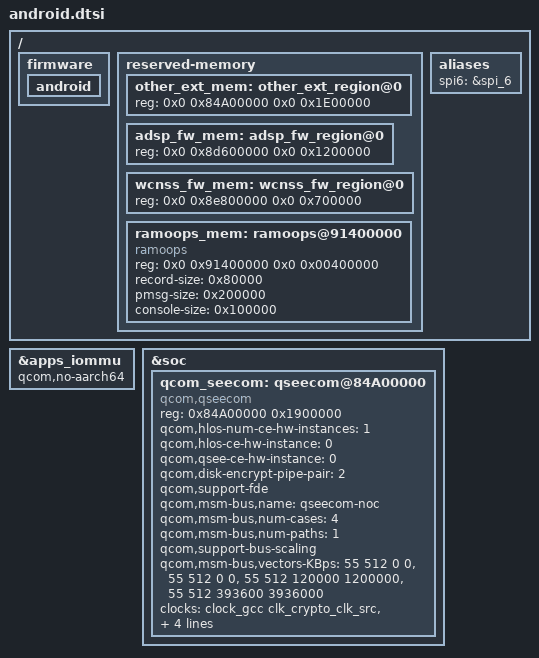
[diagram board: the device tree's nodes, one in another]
/ {
	firmware: firmware {
		android {
			/delete-node/ fstab;
			/delete-node/ vbmeta;
		};
	};

	reserved-memory {
		other_ext_mem: other_ext_region@0 {
			reg = <0x0 0x84A00000 0x0 0x1E00000>;
		};

		adsp_fw_mem: adsp_fw_region@0 {
			reg = <0x0 0x8d600000 0x0 0x1200000>;
		};

		wcnss_fw_mem: wcnss_fw_region@0 {
			reg = <0x0 0x8e800000 0x0 0x700000>;
		};

		/* ramoops: kernel log persistence across reboots.
		 * 4MB at 0x91400000 — allows grabbing last_kmsg after bootloop.
		 */
		ramoops_mem: ramoops@91400000 {
			compatible = "ramoops";
			reg = <0x0 0x91400000 0x0 0x00400000>;
			record-size = <0x80000>;
			pmsg-size = <0x200000>;
			console-size = <0x100000>;
		};
	};

	aliases {
		spi6 = &spi_6;
	};
};

&apps_iommu {
	qcom,no-aarch64;
};

&soc {
	/delete-node/ qseecom@85b00000;

	qcom_seecom: qseecom@84A00000 {
		compatible = "qcom,qseecom";
		reg = <0x84A00000 0x1900000>;
		reg-names = "secapp-region";
		qcom,hlos-num-ce-hw-instances = <1>;
		qcom,hlos-ce-hw-instance = <0>;
		qcom,qsee-ce-hw-instance = <0>;
		qcom,disk-encrypt-pipe-pair = <2>;
		qcom,support-fde;
		qcom,msm-bus,name = "qseecom-noc";
		qcom,msm-bus,num-cases = <4>;
		qcom,msm-bus,num-paths = <1>;
		qcom,support-bus-scaling;
		qcom,msm-bus,vectors-KBps =
			<55 512 0 0>,
			<55 512 0 0>,
			<55 512 120000 1200000>,
			<55 512 393600 3936000>;
		clocks = <&clock_gcc clk_crypto_clk_src>,
			 <&clock_gcc clk_gcc_crypto_clk>,
			 <&clock_gcc clk_gcc_crypto_ahb_clk>,
			 <&clock_gcc clk_gcc_crypto_axi_clk>;
		clock-names = "core_clk_src", "core_clk",
				"iface_clk", "bus_clk";
		qcom,ce-opp-freq = <100000000>;
		status = "okay";
	};
};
